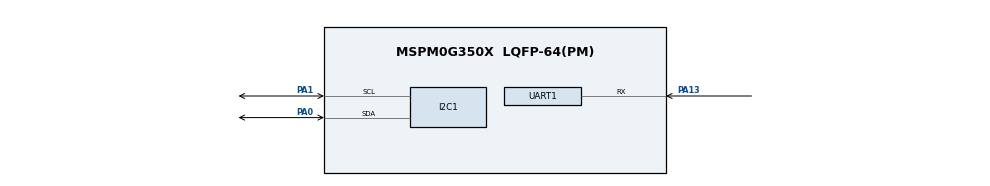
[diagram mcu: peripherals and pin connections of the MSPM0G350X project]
/**
 * @cliArgs --device "MSPM0G350X" --package "LQFP-64(PM)" --part "Default" --product "mspm0_sdk@2.01.00.03"
 * @versions {"tool":"1.20.0+3587"}
 */

/**
 * Import the modules used in this configuration.
 */
const I2C    = scripting.addModule("/ti/driverlib/I2C", {}, false);
const I2C1   = I2C.addInstance();
const SYSCTL = scripting.addModule("/ti/driverlib/SYSCTL");
const UART   = scripting.addModule("/ti/driverlib/UART", {}, false);
const UART1  = UART.addInstance();

/**
 * Write custom configuration values to the imported modules.
 */
I2C1.$name                             = "I2C_OLED";
I2C1.basicEnableController             = true;
I2C1.basicControllerStandardBusSpeed   = "Fast";
I2C1.peripheral.$assign                = "I2C0";
I2C1.peripheral.sdaPin.$assign         = "PA0";
I2C1.peripheral.sclPin.$assign         = "PA1";
I2C1.sdaPinConfig.$name                = "ti_driverlib_gpio_GPIOPinGeneric0";
I2C1.sdaPinConfig.hideOutputInversion  = scripting.forceWrite(false);
I2C1.sdaPinConfig.onlyInternalResistor = scripting.forceWrite(false);
I2C1.sdaPinConfig.passedPeripheralType = scripting.forceWrite("Digital");
I2C1.sclPinConfig.$name                = "ti_driverlib_gpio_GPIOPinGeneric1";
I2C1.sclPinConfig.hideOutputInversion  = scripting.forceWrite(false);
I2C1.sclPinConfig.onlyInternalResistor = scripting.forceWrite(false);
I2C1.sclPinConfig.passedPeripheralType = scripting.forceWrite("Digital");

const Board = scripting.addModule("/ti/driverlib/Board", {}, false);

SYSCTL.forceDefaultClkConfig = true;

UART1.$name                                = "UART_JY901S";
UART1.targetBaudRate                       = 115200;
UART1.direction                            = "RX";
UART1.enabledDMARXTriggers                 = "DL_UART_DMA_INTERRUPT_RX";
UART1.peripheral.$assign                   = "UART3";
UART1.peripheral.rxPin.$assign             = "PA13";
UART1.rxPinConfig.$name                    = "ti_driverlib_gpio_GPIOPinGeneric3";
UART1.rxPinConfig.hideOutputInversion      = scripting.forceWrite(false);
UART1.rxPinConfig.onlyInternalResistor     = scripting.forceWrite(false);
UART1.rxPinConfig.passedPeripheralType     = scripting.forceWrite("Digital");
UART1.rxPinConfig.enableConfig             = true;
UART1.rxPinConfig.internalResistor         = "PULL_UP";
UART1.DMA_CHANNEL_RX.$name                 = "DMA_UART_JY901S";
UART1.DMA_CHANNEL_RX.addressMode           = "f2b";
UART1.DMA_CHANNEL_RX.srcLength             = "BYTE";
UART1.DMA_CHANNEL_RX.dstLength             = "BYTE";
UART1.DMA_CHANNEL_RX.configureTransferSize = true;
UART1.DMA_CHANNEL_RX.transferSize          = 88;
UART1.DMA_CHANNEL_RX.transferMode          = "FULL_CH_REPEAT_SINGLE";
UART1.DMA_CHANNEL_RX.destIncrement         = "INCREMENT";

/**
 * Pinmux solution for unlocked pins/peripherals. This ensures that minor changes to the automatic solver in a future
 * version of the tool will not impact the pinmux you originally saw.  These lines can be completely deleted in order to
 * re-solve from scratch.
 */
Board.peripheral.$suggestSolution                = "DEBUGSS";
Board.peripheral.swclkPin.$suggestSolution       = "PA20";
Board.peripheral.swdioPin.$suggestSolution       = "PA19";
SYSCTL.peripheral.$suggestSolution               = "SYSCTL";
UART1.DMA_CHANNEL_RX.peripheral.$suggestSolution = "DMA_CH0";
